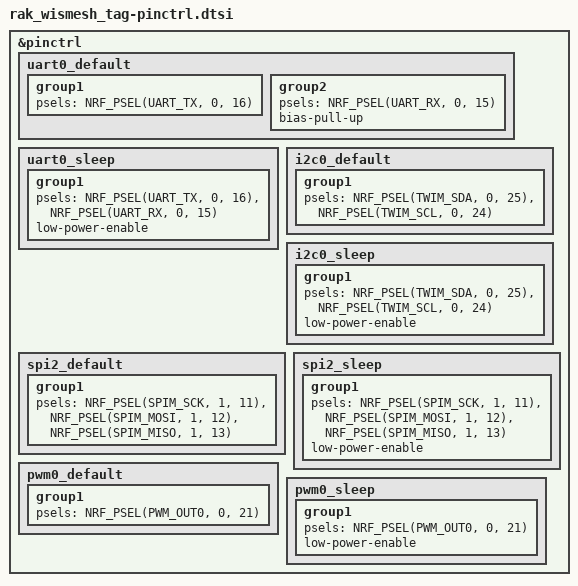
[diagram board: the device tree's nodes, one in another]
/*
 * RAK WisMesh Tag pin control definitions
 * Copyright (c) 2025 ZephCore
 *
 * SPDX-License-Identifier: MIT
 *
 * Pin mappings (from Arduino MeshCore variant.h):
 *
 * SPI2 (LoRa SX1262):  SCK=P1.11, MOSI=P1.12, MISO=P1.13, CS=P1.10
 * I2C0 (sensors):      SDA=P0.25, SCL=P0.24
 * UART0 (GPS 9600):    TX=P0.16 (→GPS RX), RX=P0.15 (←GPS TX)
 * PWM0 (buzzer):       P0.21
 */

&pinctrl {
	/* UART0 for GPS module at 9600 baud */
	uart0_default: uart0_default {
		group1 {
			psels = <NRF_PSEL(UART_TX, 0, 16)>;   /* P0.16 → GPS RX */
		};
		group2 {
			psels = <NRF_PSEL(UART_RX, 0, 15)>;   /* P0.15 ← GPS TX */
			bias-pull-up;
		};
	};

	uart0_sleep: uart0_sleep {
		group1 {
			psels = <NRF_PSEL(UART_TX, 0, 16)>,
				<NRF_PSEL(UART_RX, 0, 15)>;
			low-power-enable;
		};
	};

	/* I2C0 for sensors (LIS2DH, environment sensors) */
	i2c0_default: i2c0_default {
		group1 {
			psels = <NRF_PSEL(TWIM_SDA, 0, 25)>,   /* P0.25 */
				<NRF_PSEL(TWIM_SCL, 0, 24)>;   /* P0.24 */
		};
	};

	i2c0_sleep: i2c0_sleep {
		group1 {
			psels = <NRF_PSEL(TWIM_SDA, 0, 25)>,
				<NRF_PSEL(TWIM_SCL, 0, 24)>;
			low-power-enable;
		};
	};

	/* SPI2 for LoRa SX1262 */
	spi2_default: spi2_default {
		group1 {
			psels = <NRF_PSEL(SPIM_SCK,  1, 11)>,   /* P1.11 (Arduino 43) */
				<NRF_PSEL(SPIM_MOSI, 1, 12)>,   /* P1.12 (Arduino 44) */
				<NRF_PSEL(SPIM_MISO, 1, 13)>;   /* P1.13 (Arduino 45) */
		};
	};

	spi2_sleep: spi2_sleep {
		group1 {
			psels = <NRF_PSEL(SPIM_SCK,  1, 11)>,
				<NRF_PSEL(SPIM_MOSI, 1, 12)>,
				<NRF_PSEL(SPIM_MISO, 1, 13)>;
			low-power-enable;
		};
	};

	/* PWM0 for buzzer on P0.21 */
	pwm0_default: pwm0_default {
		group1 {
			psels = <NRF_PSEL(PWM_OUT0, 0, 21)>;
		};
	};

	pwm0_sleep: pwm0_sleep {
		group1 {
			psels = <NRF_PSEL(PWM_OUT0, 0, 21)>;
			low-power-enable;
		};
	};
};
